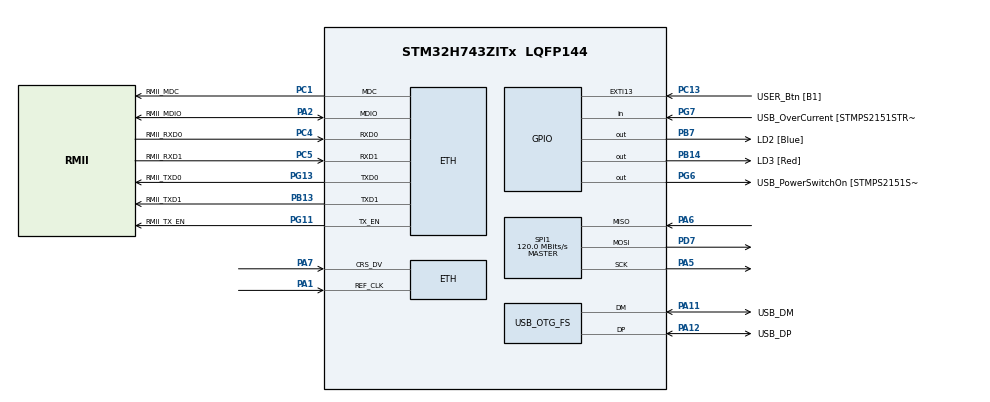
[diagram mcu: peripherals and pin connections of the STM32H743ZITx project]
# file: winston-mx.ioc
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CORTEX_M7.CPU_DCache=Enabled
CORTEX_M7.CPU_ICache=Enabled
ETH.MediaInterface=HAL_ETH_RMII_MODE
LWIP.BSP.number=1
LWIP.CHECKSUM_CHECK_ICMP=0
LWIP.CHECKSUM_GEN_ICMP=0
LWIP.Version=v2.1.2_Cube
LWIP0.BSP.STBoard=false
LWIP0.BSP.api=BSP_COMPONENT_DRIVER
LWIP0.BSP.component=LAN8742
LWIP0.BSP.i2caddr=0
LWIP0.BSP.instance=LAN8742
LWIP0.BSP.name=Driver_PHY
LWIP0.BSP.solution=LAN8742
Mcu.Family=STM32H7
Mcu.Name=STM32H743ZITx
Mcu.Package=LQFP144
NVIC.ETH_IRQn=true\:0\:0\:false\:false\:true\:true\:true
NVIC.OTG_FS_IRQn=true\:0\:0\:false\:false\:true\:false\:true
NVIC.PriorityGroup=NVIC_PRIORITYGROUP_4
PA1.Mode=RMII
PA1.Signal=ETH_REF_CLK
PA10.GPIO_Label=USB_ID
PA10.Signal=USB_OTG_FS_ID
PA11.GPIO_Label=USB_DM
PA11.Mode=Host_Only
PA11.Signal=USB_OTG_FS_DM
PA12.GPIO_Label=USB_DP
PA12.Mode=Host_Only
PA12.Signal=USB_OTG_FS_DP
PA2.GPIO_Label=RMII_MDIO
PA2.Mode=RMII
PA2.Signal=ETH_MDIO
PA5.Mode=Full_Duplex_Master
PA5.Signal=SPI1_SCK
PA6.Mode=Full_Duplex_Master
PA6.Signal=SPI1_MISO
PA7.Mode=RMII
PA7.Signal=ETH_CRS_DV
PA8.GPIO_Label=USB_SOF [TP1]
PA8.Signal=USB_OTG_FS_SOF
PA9.GPIO_Label=USB_VBUS
PA9.Signal=USB_OTG_FS_VBUS
PB13.GPIO_Label=RMII_TXD1
PB13.Mode=RMII
PB13.Signal=ETH_TXD1
PB14.GPIO_Label=LD3 [Red]
PB14.Signal=GPIO_Output
PB7.GPIO_Label=LD2 [Blue]
PB7.Signal=GPIO_Output
PC1.GPIO_Label=RMII_MDC
PC1.Mode=RMII
PC1.Signal=ETH_MDC
PC13.GPIO_Label=USER_Btn [B1]
PC13.Signal=GPXTI13
PC14-OSC32_IN\ (OSC32_IN).Mode=LSE-External-Oscillator
PC14-OSC32_IN\ (OSC32_IN).Signal=RCC_OSC32_IN
PC15-OSC32_OUT\ (OSC32_OUT).Mode=LSE-External-Oscillator
PC15-OSC32_OUT\ (OSC32_OUT).Signal=RCC_OSC32_OUT
PC4.GPIO_Label=RMII_RXD0
PC4.Mode=RMII
PC4.Signal=ETH_RXD0
PC5.GPIO_Label=RMII_RXD1
PC5.Mode=RMII
PC5.Signal=ETH_RXD1
PD7.Mode=Full_Duplex_Master
PD7.Signal=SPI1_MOSI
PD8.GPIO_Label=STLK_RX [STM32F103CBT6_PA3]
PD8.Signal=USART3_TX
PD9.GPIO_Label=STLK_TX [STM32F103CBT6_PA2]
PD9.Signal=USART3_RX
PG11.GPIO_Label=RMII_TX_EN
PG11.Mode=RMII
PG11.Signal=ETH_TX_EN
PG13.GPIO_Label=RMII_TXD0
PG13.Mode=RMII
PG13.Signal=ETH_TXD0
PG6.GPIO_Label=USB_PowerSwitchOn [STMPS2151STR_EN]
PG6.Signal=GPIO_Output
PG7.GPIO_Label=USB_OverCurrent [STMPS2151STR_FAULT]
PG7.Signal=GPIO_Input
PH0-OSC_IN\ (PH0).GPIO_Label=MCO
PH0-OSC_IN\ (PH0).Mode=HSE-External-Clock-Source
PH0-OSC_IN\ (PH0).Signal=RCC_OSC_IN
PH1-OSC_OUT\ (PH1).Signal=RCC_OSC_OUT
ProjectManager.HeapSize=0x200
ProjectManager.StackSize=0x400
ProjectManager.TargetToolchain=STM32CubeIDE
RCC.48MHZClocksFreq_Value=24000000
RCC.ADCFreq_Value=16125000
RCC.AHBFreq_Value=216000000
RCC.APB1CLKDivider=RCC_HCLK_DIV4
RCC.APB1Freq_Value=120000000
RCC.APB1TimFreq_Value=108000000
RCC.APB2CLKDivider=RCC_HCLK_DIV2
RCC.APB2Freq_Value=120000000
RCC.APB2TimFreq_Value=216000000
RCC.APB3Freq_Value=120000000
RCC.APB4Freq_Value=120000000
RCC.CortexFreq_Value=480000000
RCC.D1PPRE=RCC_APB3_DIV2
RCC.D2PPRE1=RCC_APB1_DIV2
RCC.D2PPRE2=RCC_APB2_DIV2
RCC.D3PPRE=RCC_APB4_DIV2
RCC.DIVM1=1
RCC.DIVN1=120
RCC.DIVQ1=4
RCC.HCLKFreq_Value=240000000
RCC.HPRE=RCC_HCLK_DIV2
RCC.HSE_VALUE=8000000
RCC.HSI_VALUE=64000000
RCC.PLLM=25
RCC.PLLMUL=RCC_PLL_MUL9
RCC.PLLN=432
RCC.PLLQ=9
RCC.PLLSourceVirtual=RCC_PLLSOURCE_HSE
RCC.PRESCALERUSB=RCC_USBCLKSOURCE_PLL_DIV1_5
RCC.PWR_Regulator_Voltage_Scale=PWR_REGULATOR_VOLTAGE_SCALE0
RCC.SYSCLKFreq_VALUE=480000000
RCC.SYSCLKSource=RCC_SYSCLKSOURCE_PLLCLK
RCC.SYSCLKSourceVirtual=RCC_SYSCLKSOURCE_PLLCLK
RCC.USBCLockSelection=RCC_USBCLKSOURCE_HSI48
RCC.USBFreq_Value=48000000
RCC.VCOOutputFreq_Value=432000000
SPI1.CalculateBaudRate=120.0 MBits/s
SPI1.Direction=SPI_DIRECTION_2LINES
SPI1.Mode=SPI_MODE_MASTER
SPI1.VirtualType=VM_MASTER
USB_HOST.BSP.number=1
USB_HOST.USBH_HandleTypeDef-ALL_Classes_FS=hUsbHostFS
USB_HOST.VirtualModeFS=All_Classes
USB_HOST0.BSP.STBoard=false
USB_HOST0.BSP.api=Unknown
USB_HOST0.BSP.i2caddr=0
USB_HOST0.BSP.instance=PB7
USB_HOST0.BSP.ip=GPIO
USB_HOST0.BSP.mode=Output
USB_HOST0.BSP.name=Drive_VBUS_FS
USB_HOST0.BSP.solution=PB7
USB_OTG_FS.VirtualMode=Host_Only
USB_OTG_FS.phy_itface=HCD_PHY_EMBEDDED
VP_LWIP_VS_Enabled.Mode=Enabled
VP_USB_HOST_VS_USB_HOST_ALL_CLASS_FS.Mode=ALL_Classes_FS
board=NUCLEO-H743ZI

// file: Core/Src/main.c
/* USER CODE BEGIN Header */
/**
  ******************************************************************************
  * @file           : main.c
  * @brief          : Main program body
  ******************************************************************************
  * @attention
  *
  * <h2><center>&copy; Copyright (c) 2020 STMicroelectronics.
  * All rights reserved.</center></h2>
  *
  * This software component is licensed by ST under Ultimate Liberty license
  * SLA0044, the "License"; You may not use this file except in compliance with
  * the License. You may obtain a copy of the License at:
  *                             www.st.com/SLA0044
  *
  ******************************************************************************
  */
/* USER CODE END Header */
#include "main.h"
#include "lwip.h"
#include "usb_host.h"

/* USER CODE BEGIN Includes */

#include "../../../winston/winston.h"

/* USER CODE END Includes */

SPI_HandleTypeDef hspi1;

void SystemClock_Config(void);
static void MX_GPIO_Init(void);
static void MX_SPI1_Init(void);
void MX_USB_HOST_Process(void);

int main(void)
{

  /* Enable I-Cache---------------------------------------------------------*/
  SCB_EnableICache();

  /* Enable D-Cache---------------------------------------------------------*/
  SCB_EnableDCache();

  /* MCU Configuration--------------------------------------------------------*/

  /* Reset of all peripherals, Initializes the Flash interface and the Systick. */
  HAL_Init();

  /* Configure the system clock */
  SystemClock_Config();

  /* Initialize all configured peripherals */
  MX_GPIO_Init();
  MX_SPI1_Init();
  MX_LWIP_Init();
  MX_USB_HOST_Init();
  /* USER CODE BEGIN 2 */

  // setup winston
  winston_setup();

  /* USER CODE END 2 */

  /* Infinite loop */
  while (1)
  {
    MX_USB_HOST_Process();

    /* USER CODE BEGIN 3 */
    // loop call
    winston_loop();
  }
  /* USER CODE END 3 */
}

void SystemClock_Config(void)
{
  RCC_OscInitTypeDef RCC_OscInitStruct = {0};
  RCC_ClkInitTypeDef RCC_ClkInitStruct = {0};
  RCC_PeriphCLKInitTypeDef PeriphClkInitStruct = {0};

  /** Supply configuration update enable
  */
  HAL_PWREx_ConfigSupply(PWR_LDO_SUPPLY);
  /** Configure the main internal regulator output voltage
  */
  __HAL_PWR_VOLTAGESCALING_CONFIG(PWR_REGULATOR_VOLTAGE_SCALE0);

  while(!__HAL_PWR_GET_FLAG(PWR_FLAG_VOSRDY)) {}
  /** Initializes the RCC Oscillators according to the specified parameters
  * in the RCC_OscInitTypeDef structure.
  */
  RCC_OscInitStruct.OscillatorType = RCC_OSCILLATORTYPE_HSI48|RCC_OSCILLATORTYPE_HSE;
  RCC_OscInitStruct.HSEState = RCC_HSE_BYPASS;
  RCC_OscInitStruct.HSI48State = RCC_HSI48_ON;
  RCC_OscInitStruct.PLL.PLLState = RCC_PLL_ON;
  RCC_OscInitStruct.PLL.PLLSource = RCC_PLLSOURCE_HSE;
  RCC_OscInitStruct.PLL.PLLM = 1;
  RCC_OscInitStruct.PLL.PLLN = 120;
  RCC_OscInitStruct.PLL.PLLP = 2;
  RCC_OscInitStruct.PLL.PLLQ = 4;
  RCC_OscInitStruct.PLL.PLLR = 2;
  RCC_OscInitStruct.PLL.PLLRGE = RCC_PLL1VCIRANGE_3;
  RCC_OscInitStruct.PLL.PLLVCOSEL = RCC_PLL1VCOWIDE;
  RCC_OscInitStruct.PLL.PLLFRACN = 0;
  if (HAL_RCC_OscConfig(&RCC_OscInitStruct) != HAL_OK)
  {
    Error_Handler();
  }
  /** Initializes the CPU, AHB and APB buses clocks
  */
  RCC_ClkInitStruct.ClockType = RCC_CLOCKTYPE_HCLK|RCC_CLOCKTYPE_SYSCLK
                              |RCC_CLOCKTYPE_PCLK1|RCC_CLOCKTYPE_PCLK2
                              |RCC_CLOCKTYPE_D3PCLK1|RCC_CLOCKTYPE_D1PCLK1;
  RCC_ClkInitStruct.SYSCLKSource = RCC_SYSCLKSOURCE_PLLCLK;
  RCC_ClkInitStruct.SYSCLKDivider = RCC_SYSCLK_DIV1;
  RCC_ClkInitStruct.AHBCLKDivider = RCC_HCLK_DIV2;
  RCC_ClkInitStruct.APB3CLKDivider = RCC_APB3_DIV2;
  RCC_ClkInitStruct.APB1CLKDivider = RCC_APB1_DIV2;
  RCC_ClkInitStruct.APB2CLKDivider = RCC_APB2_DIV2;
  RCC_ClkInitStruct.APB4CLKDivider = RCC_APB4_DIV2;

  if (HAL_RCC_ClockConfig(&RCC_ClkInitStruct, FLASH_LATENCY_4) != HAL_OK)
  {
    Error_Handler();
  }
  PeriphClkInitStruct.PeriphClockSelection = RCC_PERIPHCLK_SPI1|RCC_PERIPHCLK_USB;
  PeriphClkInitStruct.Spi123ClockSelection = RCC_SPI123CLKSOURCE_PLL;
  PeriphClkInitStruct.UsbClockSelection = RCC_USBCLKSOURCE_HSI48;
  if (HAL_RCCEx_PeriphCLKConfig(&PeriphClkInitStruct) != HAL_OK)
  {
    Error_Handler();
  }
  /** Enable USB Voltage detector
  */
  HAL_PWREx_EnableUSBVoltageDetector();
}

static void MX_SPI1_Init(void)
{

  /* SPI1 parameter configuration*/
  hspi1.Instance = SPI1;
  hspi1.Init.Mode = SPI_MODE_MASTER;
  hspi1.Init.Direction = SPI_DIRECTION_2LINES;
  hspi1.Init.DataSize = SPI_DATASIZE_4BIT;
  hspi1.Init.CLKPolarity = SPI_POLARITY_LOW;
  hspi1.Init.CLKPhase = SPI_PHASE_1EDGE;
  hspi1.Init.NSS = SPI_NSS_SOFT;
  hspi1.Init.BaudRatePrescaler = SPI_BAUDRATEPRESCALER_2;
  hspi1.Init.FirstBit = SPI_FIRSTBIT_MSB;
  hspi1.Init.TIMode = SPI_TIMODE_DISABLE;
  hspi1.Init.CRCCalculation = SPI_CRCCALCULATION_DISABLE;
  hspi1.Init.CRCPolynomial = 0x0;
  hspi1.Init.NSSPMode = SPI_NSS_PULSE_ENABLE;
  hspi1.Init.NSSPolarity = SPI_NSS_POLARITY_LOW;
  hspi1.Init.FifoThreshold = SPI_FIFO_THRESHOLD_01DATA;
  hspi1.Init.TxCRCInitializationPattern = SPI_CRC_INITIALIZATION_ALL_ZERO_PATTERN;
  hspi1.Init.RxCRCInitializationPattern = SPI_CRC_INITIALIZATION_ALL_ZERO_PATTERN;
  hspi1.Init.MasterSSIdleness = SPI_MASTER_SS_IDLENESS_00CYCLE;
  hspi1.Init.MasterInterDataIdleness = SPI_MASTER_INTERDATA_IDLENESS_00CYCLE;
  hspi1.Init.MasterReceiverAutoSusp = SPI_MASTER_RX_AUTOSUSP_DISABLE;
  hspi1.Init.MasterKeepIOState = SPI_MASTER_KEEP_IO_STATE_DISABLE;
  hspi1.Init.IOSwap = SPI_IO_SWAP_DISABLE;
  if (HAL_SPI_Init(&hspi1) != HAL_OK)
  {
    Error_Handler();
  }

}

static void MX_GPIO_Init(void)
{
  GPIO_InitTypeDef GPIO_InitStruct = {0};

  /* GPIO Ports Clock Enable */
  __HAL_RCC_GPIOC_CLK_ENABLE();
  __HAL_RCC_GPIOH_CLK_ENABLE();
  __HAL_RCC_GPIOA_CLK_ENABLE();
  __HAL_RCC_GPIOB_CLK_ENABLE();
  __HAL_RCC_GPIOD_CLK_ENABLE();
  __HAL_RCC_GPIOG_CLK_ENABLE();

  /*Configure GPIO pin Output Level */
  HAL_GPIO_WritePin(GPIOB, LD3_Pin|LD2_Pin, GPIO_PIN_RESET);

  /*Configure GPIO pin Output Level */
  HAL_GPIO_WritePin(USB_PowerSwitchOn_GPIO_Port, USB_PowerSwitchOn_Pin, GPIO_PIN_RESET);

  /*Configure GPIO pin : USER_Btn_Pin */
  GPIO_InitStruct.Pin = USER_Btn_Pin;
  GPIO_InitStruct.Mode = GPIO_MODE_IT_RISING;
  GPIO_InitStruct.Pull = GPIO_NOPULL;
  HAL_GPIO_Init(USER_Btn_GPIO_Port, &GPIO_InitStruct);

  /*Configure GPIO pins : LD3_Pin LD2_Pin */
  GPIO_InitStruct.Pin = LD3_Pin|LD2_Pin;
  GPIO_InitStruct.Mode = GPIO_MODE_OUTPUT_PP;
  GPIO_InitStruct.Pull = GPIO_NOPULL;
  GPIO_InitStruct.Speed = GPIO_SPEED_FREQ_LOW;
  HAL_GPIO_Init(GPIOB, &GPIO_InitStruct);

  /*Configure GPIO pins : STLK_RX_Pin STLK_TX_Pin */
  GPIO_InitStruct.Pin = STLK_RX_Pin|STLK_TX_Pin;
  GPIO_InitStruct.Mode = GPIO_MODE_AF_PP;
  GPIO_InitStruct.Pull = GPIO_NOPULL;
  GPIO_InitStruct.Speed = GPIO_SPEED_FREQ_LOW;
  GPIO_InitStruct.Alternate = GPIO_AF7_USART3;
  HAL_GPIO_Init(GPIOD, &GPIO_InitStruct);

  /*Configure GPIO pin : USB_PowerSwitchOn_Pin */
  GPIO_InitStruct.Pin = USB_PowerSwitchOn_Pin;
  GPIO_InitStruct.Mode = GPIO_MODE_OUTPUT_PP;
  GPIO_InitStruct.Pull = GPIO_NOPULL;
  GPIO_InitStruct.Speed = GPIO_SPEED_FREQ_LOW;
  HAL_GPIO_Init(USB_PowerSwitchOn_GPIO_Port, &GPIO_InitStruct);

  /*Configure GPIO pin : USB_OverCurrent_Pin */
  GPIO_InitStruct.Pin = USB_OverCurrent_Pin;
  GPIO_InitStruct.Mode = GPIO_MODE_INPUT;
  GPIO_InitStruct.Pull = GPIO_NOPULL;
  HAL_GPIO_Init(USB_OverCurrent_GPIO_Port, &GPIO_InitStruct);

}

void Error_Handler(void)
{
  __disable_irq();
  while (1)
  {
  }
}

/************************ (C) COPYRIGHT STMicroelectronics *****END OF FILE****/
